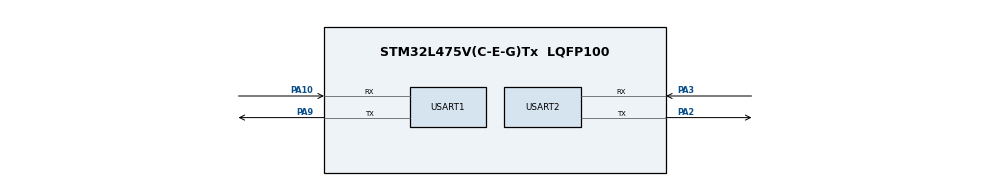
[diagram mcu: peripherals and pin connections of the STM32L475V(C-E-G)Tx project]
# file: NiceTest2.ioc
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FREERTOS.Tasks01=defaultTask,0,128,StartDefaultTask,Default,NULL,Dynamic,NULL,NULL;printHello,-2,128,StartPrintHello,Default,"printHello",Dynamic,NULL,NULL
Mcu.Family=STM32L4
Mcu.Name=STM32L475V(C-E-G)Tx
Mcu.Package=LQFP100
NVIC.PriorityGroup=NVIC_PRIORITYGROUP_4
NVIC.TIM6_DAC_IRQn=true\:0\:0\:false\:false\:true\:false\:false\:true
NVIC.TimeBase=TIM6_DAC_IRQn
NVIC.TimeBaseIP=TIM6
PA10.Mode=Asynchronous
PA10.Signal=USART1_RX
PA2.Mode=Asynchronous
PA2.Signal=USART2_TX
PA3.Mode=Asynchronous
PA3.Signal=USART2_RX
PA9.Mode=Asynchronous
PA9.Signal=USART1_TX
ProjectManager.HeapSize=0x200
ProjectManager.StackSize=0x400
ProjectManager.TargetToolchain=STM32CubeIDE
RCC.HSE_VALUE=8000000
RCC.HSI_VALUE=16000000
RCC.LSE_VALUE=32768
RCC.MSI_VALUE=4000000
RCC.VCOOutputFreq_Value=32000000
USART1.VirtualMode-Asynchronous=VM_ASYNC
USART2.VirtualMode-Asynchronous=VM_ASYNC
VP_FREERTOS_VS_CMSIS_V1.Mode=CMSIS_V1
VP_SYS_VS_tim6.Mode=TIM6
board=custom

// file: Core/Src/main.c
/* USER CODE BEGIN Header */
/**
  ******************************************************************************
  * @file           : main.c
  * @brief          : Main program body
  ******************************************************************************
  * @attention
  *
  * <h2><center>&copy; Copyright (c) 2021 STMicroelectronics.
  * All rights reserved.</center></h2>
  *
  * This software component is licensed by ST under BSD 3-Clause license,
  * the "License"; You may not use this file except in compliance with the
  * License. You may obtain a copy of the License at:
  *                        opensource.org/licenses/BSD-3-Clause
  *
  ******************************************************************************
  */
/* USER CODE END Header */
#include "main.h"
#include "cmsis_os.h"

/* USER CODE BEGIN Includes */
#include <stdio.h>
#include <errno.h>
#include <sys/unistd.h>
// #include "retarget.h"

/* USER CODE END Includes */

UART_HandleTypeDef huart1;
UART_HandleTypeDef huart2;

osThreadId defaultTaskHandle;
osThreadId printHelloHandle;

void SystemClock_Config(void);
static void MX_GPIO_Init(void);
static void MX_USART2_UART_Init(void);
static void MX_USART1_UART_Init(void);
void StartDefaultTask(void const * argument);
void StartPrintHello(void const * argument);

/* USER CODE BEGIN PFP */
// int _write(int file, char *ptr, int len);
void RetargetInit(UART_HandleTypeDef *huart);

/* USER CODE END PFP */

/* USER CODE BEGIN 0 */

/* int _write(int file, char *ptr, int len){
	HAL_UART_Transmit(&huart2, (uint8_t *)ptr, len, 10);
	return len;
}*/

int _write(int file, char *data, int len)
{
	if ((file != STDOUT_FILENO) && (file != STDERR_FILENO))
	{
		errno = EBADF;
		return -1;
	}

	// arbitrary timeout 1000
	HAL_StatusTypeDef status =
			HAL_UART_Transmit(&huart1, (uint8_t*)data, len, 1000);

	// return # of bytes written - as best we can tell
	return (status == HAL_OK ? len: 0);
}

/* USER CODE END 0 */

int main(void)
{

  /* MCU Configuration--------------------------------------------------------*/

  /* Reset of all peripherals, Initializes the Flash interface and the Systick. */
  HAL_Init();

  /* Configure the system clock */
  SystemClock_Config();

  /* Initialize all configured peripherals */
  MX_GPIO_Init();
  MX_USART2_UART_Init();
  MX_USART1_UART_Init();

  /* Create the thread(s) */
  /* definition and creation of defaultTask */
  osThreadDef(defaultTask, StartDefaultTask, osPriorityNormal, 0, 128);
  defaultTaskHandle = osThreadCreate(osThread(defaultTask), NULL);

  /* definition and creation of printHello */
  osThreadDef(printHello, StartPrintHello, osPriorityLow, 0, 128);
  printHelloHandle = osThreadCreate(osThread(printHello), (void*) "printHello");

  /* Start scheduler */
  osKernelStart();

  /* We should never get here as control is now taken by the scheduler */
  /* Infinite loop */
  while (1)
  {

  }
}

void SystemClock_Config(void)
{
  RCC_OscInitTypeDef RCC_OscInitStruct = {0};
  RCC_ClkInitTypeDef RCC_ClkInitStruct = {0};
  RCC_PeriphCLKInitTypeDef PeriphClkInit = {0};

  /** Initializes the RCC Oscillators according to the specified parameters
  * in the RCC_OscInitTypeDef structure.
  */
  RCC_OscInitStruct.OscillatorType = RCC_OSCILLATORTYPE_MSI;
  RCC_OscInitStruct.MSIState = RCC_MSI_ON;
  RCC_OscInitStruct.MSICalibrationValue = 0;
  RCC_OscInitStruct.MSIClockRange = RCC_MSIRANGE_6;
  RCC_OscInitStruct.PLL.PLLState = RCC_PLL_NONE;
  if (HAL_RCC_OscConfig(&RCC_OscInitStruct) != HAL_OK)
  {
    Error_Handler();
  }
  /** Initializes the CPU, AHB and APB buses clocks
  */
  RCC_ClkInitStruct.ClockType = RCC_CLOCKTYPE_HCLK|RCC_CLOCKTYPE_SYSCLK
                              |RCC_CLOCKTYPE_PCLK1|RCC_CLOCKTYPE_PCLK2;
  RCC_ClkInitStruct.SYSCLKSource = RCC_SYSCLKSOURCE_MSI;
  RCC_ClkInitStruct.AHBCLKDivider = RCC_SYSCLK_DIV1;
  RCC_ClkInitStruct.APB1CLKDivider = RCC_HCLK_DIV1;
  RCC_ClkInitStruct.APB2CLKDivider = RCC_HCLK_DIV1;

  if (HAL_RCC_ClockConfig(&RCC_ClkInitStruct, FLASH_LATENCY_0) != HAL_OK)
  {
    Error_Handler();
  }
  PeriphClkInit.PeriphClockSelection = RCC_PERIPHCLK_USART1|RCC_PERIPHCLK_USART2;
  PeriphClkInit.Usart1ClockSelection = RCC_USART1CLKSOURCE_PCLK2;
  PeriphClkInit.Usart2ClockSelection = RCC_USART2CLKSOURCE_PCLK1;
  if (HAL_RCCEx_PeriphCLKConfig(&PeriphClkInit) != HAL_OK)
  {
    Error_Handler();
  }
  /** Configure the main internal regulator output voltage
  */
  if (HAL_PWREx_ControlVoltageScaling(PWR_REGULATOR_VOLTAGE_SCALE1) != HAL_OK)
  {
    Error_Handler();
  }
}

static void MX_USART1_UART_Init(void)
{

  huart1.Instance = USART1;
  huart1.Init.BaudRate = 115200;
  huart1.Init.WordLength = UART_WORDLENGTH_8B;
  huart1.Init.StopBits = UART_STOPBITS_1;
  huart1.Init.Parity = UART_PARITY_NONE;
  huart1.Init.Mode = UART_MODE_TX_RX;
  huart1.Init.HwFlowCtl = UART_HWCONTROL_NONE;
  huart1.Init.OverSampling = UART_OVERSAMPLING_16;
  huart1.Init.OneBitSampling = UART_ONE_BIT_SAMPLE_DISABLE;
  huart1.AdvancedInit.AdvFeatureInit = UART_ADVFEATURE_NO_INIT;
  if (HAL_UART_Init(&huart1) != HAL_OK)
  {
    Error_Handler();
  }

}

static void MX_USART2_UART_Init(void)
{

  huart2.Instance = USART2;
  huart2.Init.BaudRate = 115200;
  huart2.Init.WordLength = UART_WORDLENGTH_8B;
  huart2.Init.StopBits = UART_STOPBITS_1;
  huart2.Init.Parity = UART_PARITY_NONE;
  huart2.Init.Mode = UART_MODE_TX_RX;
  huart2.Init.HwFlowCtl = UART_HWCONTROL_NONE;
  huart2.Init.OverSampling = UART_OVERSAMPLING_16;
  huart2.Init.OneBitSampling = UART_ONE_BIT_SAMPLE_DISABLE;
  huart2.AdvancedInit.AdvFeatureInit = UART_ADVFEATURE_NO_INIT;
  if (HAL_UART_Init(&huart2) != HAL_OK)
  {
    Error_Handler();
  }

}

static void MX_GPIO_Init(void)
{

  /* GPIO Ports Clock Enable */
  __HAL_RCC_GPIOA_CLK_ENABLE();

}

void StartDefaultTask(void const * argument)
{
  /* USER CODE BEGIN 5 */
  /* Infinite loop */
  for(;;)
  {
    osDelay(1000);
  }
  /* USER CODE END 5 */
}

void StartPrintHello(void const * argument)
{
  /* USER CODE BEGIN StartPrintHello */
  /* Infinite loop */
  for(;;)
  {
	  printf("Hello\r\n");
	  osDelay(1000);

  }
  /* USER CODE END StartPrintHello */
}

 /**
  * @brief  Period elapsed callback in non blocking mode
  * @note   This function is called  when TIM6 interrupt took place, inside
  * HAL_TIM_IRQHandler(). It makes a direct call to HAL_IncTick() to increment
  * a global variable "uwTick" used as application time base.
  * @param  htim : TIM handle
  * @retval None
  */
void HAL_TIM_PeriodElapsedCallback(TIM_HandleTypeDef *htim)
{
  if (htim->Instance == TIM6) {
    HAL_IncTick();
  }
}

void Error_Handler(void)
{
  __disable_irq();
  while (1)
  {
  }
}

/************************ (C) COPYRIGHT STMicroelectronics *****END OF FILE****/
